# SRAMCTRL register map
Vendor: Texas Instruments
Peripheral module from a debugger description file (folder CC27xxx7).
Registers are 32-bit, read-only, reset 0x0 unless marked. A register's access mark holds for its fields unless they carry their own. Offsets are as the file gives them; lines under a group give offsets from that group; [hi:lo] are bit positions; {n}, {i} and the like mark numbered series; 'fields as' and 'values as' point back to an identical list; <NAME> marks a mode.

## SRAMCTRL — System SRAM Controller
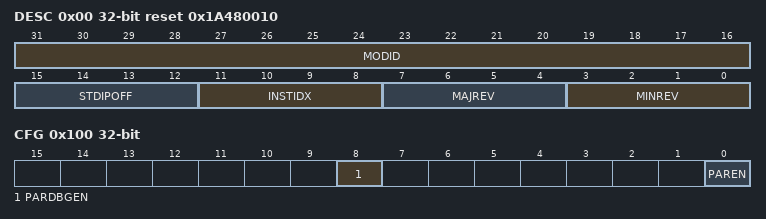
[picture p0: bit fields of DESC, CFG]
0x00 DESC reset 0x1A480010 — This register identifies the peripheral
  [31:16] MODID — Module identifier
  [15:12] STDIPOFF — 64 B Standard IP MMR block$lt;br$gt;0: STDIP MMRs do not exist$lt;br$gt;1:15: These MMRs begin at offset 64*STDIPOFF from IP base address
  [11:8] INSTIDX — IP Instance number
  [7:4] MAJREV — Major revision
  [3:0] MINREV — Minor revision
0x100 CFG access per field — Configuration Register
  [8] PARDBGEN rw — SRAM Parity Debug Enable.
    1=EN (Enable Parity Debug. An address offset can be written to PARDBG.ADDR and parity errors will be generated on reads from within this offset); 0=DIS (Disable Parity Debug. Normal operation)
  [0] PAREN rw — SRAM Parity Enable.
    1=EN (Enable Parity); 0=DIS (Disable Parity)
0x110 PARDBG access per field — Parity error check debug address setting
  [19:2] ADDR rw — Debug Parity Error Address Offset.##br##When CFG.PARDBGEN is 1, this field is used to set a parity debug address offset. Writes within this address offset will force incorrect parity bits to be stored together with the data written. The following reads within this same address offset will thus result in parity errors to be generated.
0x114 PARERR — Parity error
  [31:0] ADDR — Parity Error Address Offset.##br##This holds the address offset that first generated the parity error and an interrupt is generated. ##br##This register is 'Clear-On-Read'
